AUTOSAR XML (schema 4-0-3)
package /ComponentTypes
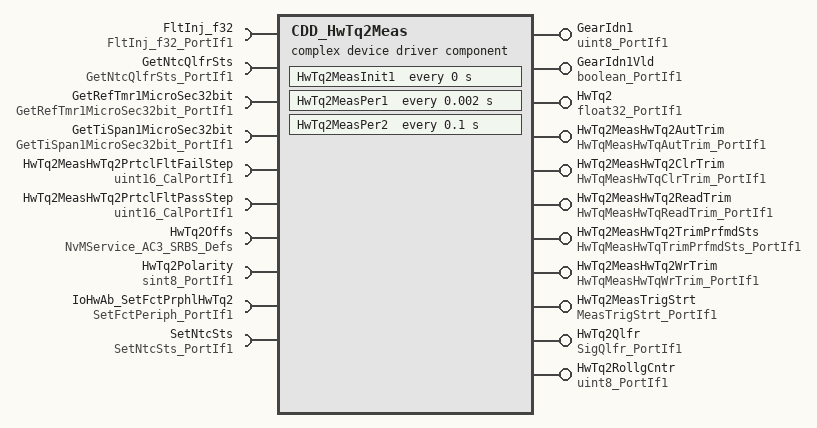
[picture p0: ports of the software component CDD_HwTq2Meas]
  complex device driver sw component type CDD_HwTq2Meas
    11 x provide port:
      GearIdn1: nonqueued-sender-com-spec{data-element=Val, init-value=0}, provided-interface=uint8_PortIf1
      GearIdn1Vld: nonqueued-sender-com-spec{data-element=Logl, init-value=0}, provided-interface=boolean_PortIf1
      HwTq2: nonqueued-sender-com-spec{data-element=Val, init-value=0}, provided-interface=float32_PortIf1
      HwTq2MeasHwTq2AutTrim: server-com-spec{operation=Oper, queue-length=1}, provided-interface=HwTqMeasHwTqAutTrim_PortIf1
      HwTq2MeasHwTq2ClrTrim: server-com-spec{operation=Oper, queue-length=1}, provided-interface=HwTqMeasHwTqClrTrim_PortIf1
      HwTq2MeasHwTq2ReadTrim: server-com-spec{operation=Oper, queue-length=1}, provided-interface=HwTqMeasHwTqReadTrim_PortIf1
      HwTq2MeasHwTq2TrimPrfmdSts: server-com-spec{operation=Oper, queue-length=1}, provided-interface=HwTqMeasHwTqTrimPrfmdSts_PortIf1
      HwTq2MeasHwTq2WrTrim: server-com-spec{operation=Oper, queue-length=1}, provided-interface=HwTqMeasHwTqWrTrim_PortIf1
      HwTq2MeasTrigStrt: server-com-spec{operation=Oper, queue-length=1}, provided-interface=MeasTrigStrt_PortIf1
      HwTq2Qlfr: nonqueued-sender-com-spec{data-element=Val, init-value=0}, provided-interface=SigQlfr_PortIf1
      HwTq2RollgCntr: nonqueued-sender-com-spec{data-element=Val, init-value=0}, provided-interface=uint8_PortIf1
    10 x require port:
      FltInj_f32: required-interface=FltInj_f32_PortIf1
      GetNtcQlfrSts: required-interface=GetNtcQlfrSts_PortIf1
      GetRefTmr1MicroSec32bit: required-interface=GetRefTmr1MicroSec32bit_PortIf1
      GetTiSpan1MicroSec32bit: required-interface=GetTiSpan1MicroSec32bit_PortIf1
      HwTq2MeasHwTq2PrtclFltFailStep: parameter-require-com-spec{init-value=2521, parameter=Val}, required-interface=uint16_CalPortIf1
      HwTq2MeasHwTq2PrtclFltPassStep: parameter-require-com-spec{init-value=1000, parameter=Val}, required-interface=uint16_CalPortIf1
      HwTq2Offs: required-interface=NvMService_AC3_SRBS_Defs
      HwTq2Polarity: nonqueued-receiver-com-spec{data-element=Val, filter=data-filter-type=ALWAYS, init-value=1}, required-interface=sint8_PortIf1
      IoHwAb_SetFctPrphlHwTq2: required-interface=SetFctPeriph_PortIf1
      SetNtcSts: required-interface=SetNtcSts_PortIf1
    behavior CDD_HwTq2Meas_InternalBehavior
      ar-typed-per-instance-memorys:
        8 x data, all with sw-calibration-access=READ-ONLY:
          GearIdn1Avl: type=boolean
          GearIdn1Data: type=uint8
          HwTq2ComStsErrCntr: type=uint8
          HwTq2IntSnsrErrCntr: type=uint8
          HwTq2MeasPrevHwTq2: type=float32
          HwTq2MeasPrevRollgCntr: type=uint8
          HwTq2MsgMissRxCnt: type=uint32
          HwTq2Offs: type=HwTqOffsRec1
      5 x operation invoked event:
        OIT_HwTq2MeasHwTq2AutTrim_Oper_HwTq2MeasHwTq2AutTrim_Oper: start-on-event=HwTq2MeasHwTq2AutTrim_Oper, operation=HwTq2MeasHwTq2AutTrim.Oper
        OIT_HwTq2MeasHwTq2ClrTrim_Oper_HwTq2MeasHwTq2ClrTrim_Oper: start-on-event=HwTq2MeasHwTq2ClrTrim_Oper, operation=HwTq2MeasHwTq2ClrTrim.Oper
        OIT_HwTq2MeasHwTq2ReadTrim_Oper_HwTq2MeasHwTq2ReadTrim_Oper: start-on-event=HwTq2MeasHwTq2ReadTrim_Oper, operation=HwTq2MeasHwTq2ReadTrim.Oper
        OIT_HwTq2MeasHwTq2TrimPrfmdSts_Oper_HwTq2MeasHwTq2TrimPrfmdSts_Oper: start-on-event=HwTq2MeasHwTq2TrimPrfmdSts_Oper, operation=HwTq2MeasHwTq2TrimPrfmdSts.Oper
        OIT_HwTq2MeasHwTq2WrTrim_Oper_HwTq2MeasHwTq2WrTrim_Oper: start-on-event=HwTq2MeasHwTq2WrTrim_Oper, operation=HwTq2MeasHwTq2WrTrim.Oper
      timing event HwTq2MeasInit1_InitEvent: start-on-event=HwTq2MeasInit1, period=0
      timing event TMT_HwTq2MeasPer1: start-on-event=HwTq2MeasPer1, period=0.002
      timing event TMT_HwTq2MeasPer3: start-on-event=HwTq2MeasPer2, period=0.1
      operation invoked event OIT_HwTq2MeasTrigStrt_Oper_HwTq2MeasTrigStrt_Oper: start-on-event=HwTq2MeasTrigStrt_Oper, operation=HwTq2MeasTrigStrt.Oper
      9 x runnable:
        HwTq2MeasHwTq2AutTrim_Oper
          sync call SC_HwTq2Offs_SetRamBlockStatus: operation=HwTq2Offs.SetRamBlockStatus, timeout=0
        HwTq2MeasHwTq2ClrTrim_Oper
          sync call SC_HwTq2Offs_SetRamBlockStatus: operation=HwTq2Offs.SetRamBlockStatus, timeout=0
        HwTq2MeasHwTq2ReadTrim_Oper
        HwTq2MeasHwTq2TrimPrfmdSts_Oper
        HwTq2MeasHwTq2WrTrim_Oper
          sync call SC_HwTq2Offs_SetRamBlockStatus: operation=HwTq2Offs.SetRamBlockStatus, timeout=0
        HwTq2MeasInit1
          sync call SC_GetRefTmr1MicroSec32bit_Oper: operation=GetRefTmr1MicroSec32bit.Oper, timeout=0
          sync call SC_GetTiSpan1MicroSec32bit_Oper: operation=GetTiSpan1MicroSec32bit.Oper, timeout=0
          sync call SC_IoHwAb_SetFctPrphlHwTq2_Oper: operation=IoHwAb_SetFctPrphlHwTq2.Oper, timeout=0
        HwTq2MeasPer1
          data-receive-point-by-arguments:
            access REC_HwTq0Polarity_Val: accessed-variable=HwTq2Polarity.Val
          data-send-points:
            5 x access:
              SEND_GearIdn1_Val: accessed-variable=GearIdn1.Val
              SEND_GearIdn1Vld_Logl: accessed-variable=GearIdn1Vld.Logl
              SEND_HwTq0_Val: accessed-variable=HwTq2.Val
              SEND_HwTq0Qlfr_Val: accessed-variable=HwTq2Qlfr.Val
              SEND_HwTq0RollgCntr_Val: accessed-variable=HwTq2RollgCntr.Val
          sync call SC_FltInj_f32_Oper: operation=FltInj_f32.Oper, timeout=0
          sync call SC_GetNtcQlfrSts_Oper: operation=GetNtcQlfrSts.Oper, timeout=0
          sync call SC_SetNtcSts_Oper: operation=SetNtcSts.Oper, timeout=0
        HwTq2MeasPer2
          sync call SC_SetNtcSts_Oper: operation=SetNtcSts.Oper, timeout=0
        HwTq2MeasTrigStrt_Oper
          sync call SC_GetRefTmr1MicroSec32bit_Oper: operation=GetRefTmr1MicroSec32bit.Oper, timeout=0
          sync call SC_GetTiSpan1MicroSec32bit_Oper: operation=GetTiSpan1MicroSec32bit.Oper, timeout=0
      swc service dependency NvmHwTq2Offs: assigned-datas=[{role=ramBlock, used-data-element=HwTq2Offs}, {role=defaultValue, used-parameter-element=HwTq2OffsDft}]
        assigned-ports:
          port-prototype=HwTq2Offs, role=NvMService_AC3_SRBS_Defs
          port-prototype=HwTq2Offs, role=NvMService_AC3_SRBS_Defs
        service-needs:
          nv block needs NvmHwTq2Offs: n-data-sets=0, readonly=false, reliability=ERROR-DETECTION, resistant-to-changed-sw=true, restore-at-start=true, store-at-shutdown=true, write-only-once=false, writing-frequency=0, writing-priority=LOW
      shared-parameters:
        parameter data prototype HwTq2OffsDft: sw-calibration-access=READ-WRITE, type=HwTqOffsRec1, init-value=fields=[OffsTrim:0, OffsTrimPrfmdSts:0]
  swc implementation CDD_HwTq2Meas_Implementation: behavior=CDD_HwTq2Meas_InternalBehavior
    code-descriptors:
      code Default: artifact-descriptors=autosar-engineering-object={short-label=Default, category=SWSRC}
